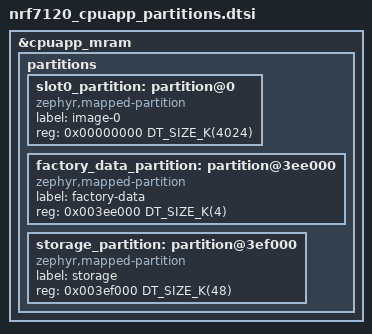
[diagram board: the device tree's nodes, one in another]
/*
 * Copyright (c) 2026 Nordic Semiconductor ASA
 *
 * SPDX-License-Identifier: LicenseRef-Nordic-5-Clause
 */

/delete-node/ &boot_partition;
/delete-node/ &slot0_partition;
/delete-node/ &slot1_partition;
/delete-node/ &storage_partition;

&cpuapp_mram {
	partitions {
		slot0_partition: partition@0 {
			compatible = "zephyr,mapped-partition";
			label = "image-0";
			reg = <0x00000000 DT_SIZE_K(4024)>;
		};

		factory_data_partition: partition@3ee000 {
			compatible = "zephyr,mapped-partition";
			label = "factory-data";
			reg = <0x003ee000 DT_SIZE_K(4)>;
		};

		storage_partition: partition@3ef000 {
			compatible = "zephyr,mapped-partition";
			label = "storage";
			reg = <0x003ef000 DT_SIZE_K(48)>;
		};
	};
};
